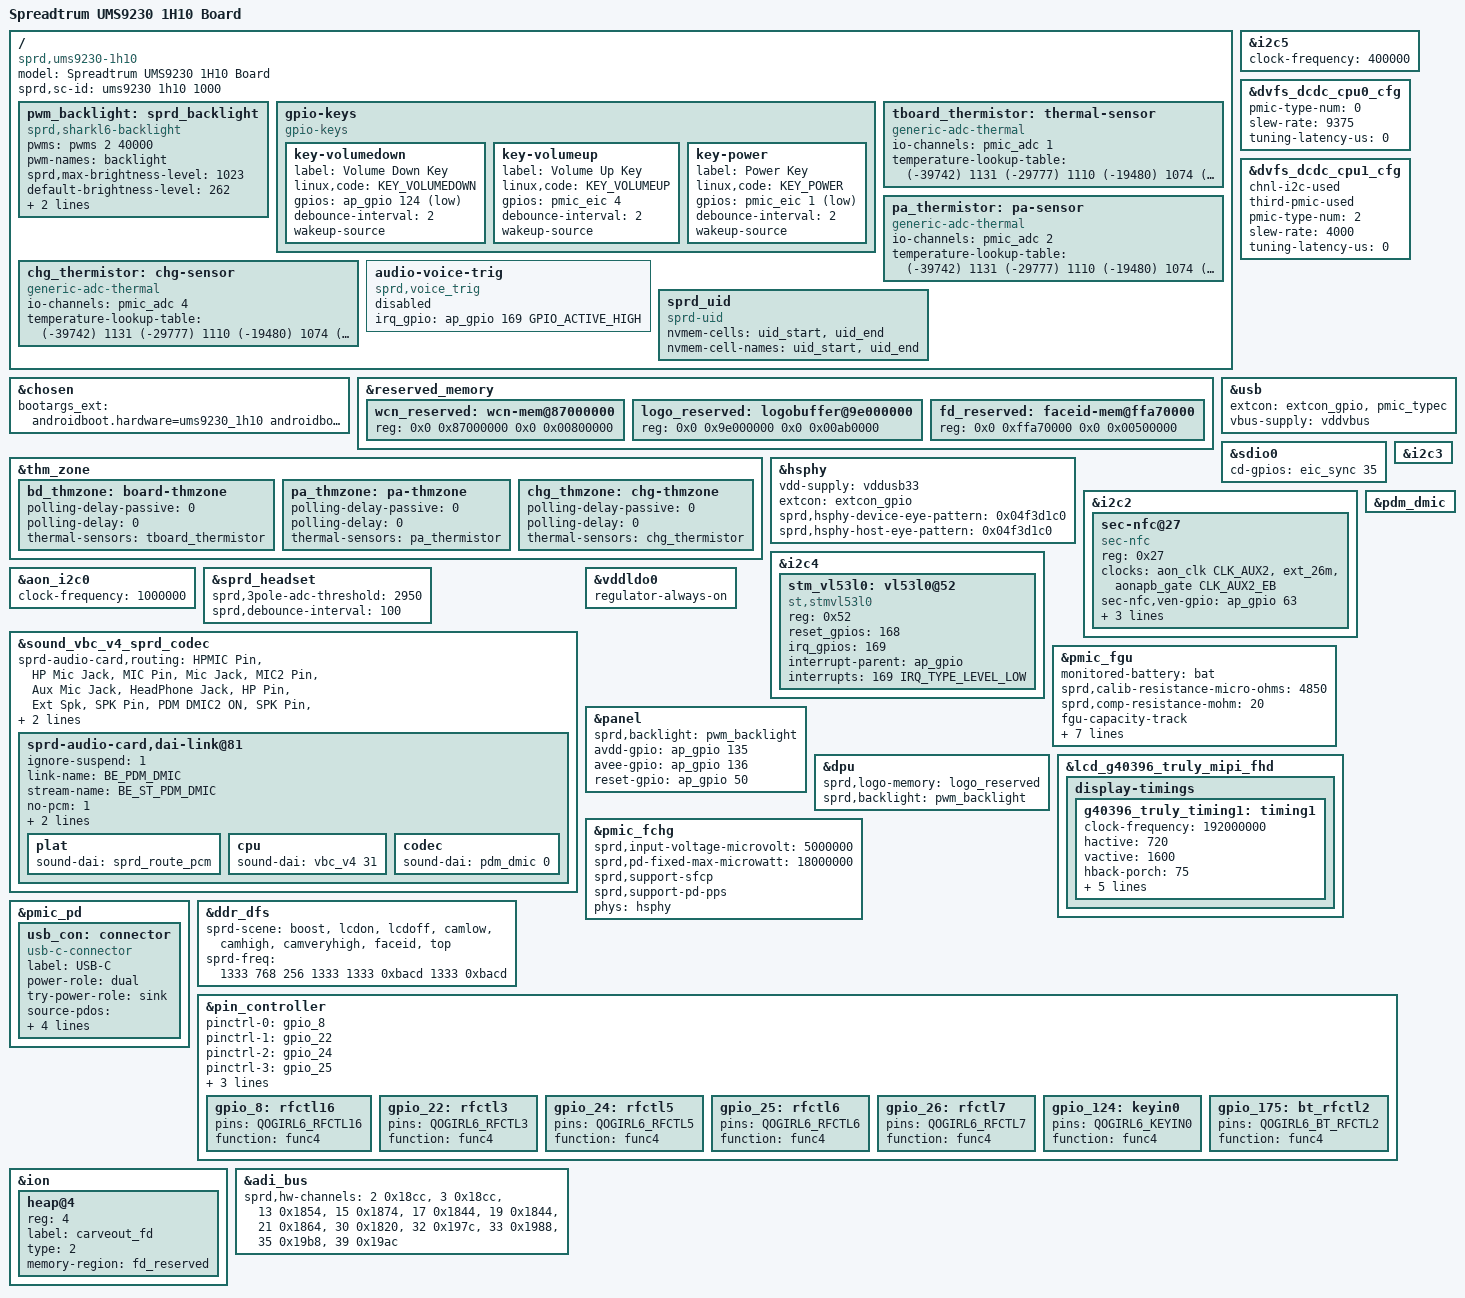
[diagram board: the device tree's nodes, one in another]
/dts-v1/;
/plugin/;
#include <dt-bindings/input/input.h>
#include <dt-bindings/gpio/gpio.h>
#include <dt-bindings/interrupt-controller/arm-gic.h>
#include <dt-bindings/clock/sprd,ums9230-clk.h>
#include <dt-bindings/mfd/sprd,sc2730-regs.h>
#include <dt-bindings/mfd/sprd,sc2730-mask.h>
#include <dt-bindings/usb/pd.h>
#include "../lcd/lcd_g40396_truly_mipi_fhd.dtsi"
#include "../lcd/lcd_dummy_mipi.dtsi"
#include "../ums9230-wcn.dtsi"

/ {

	model = "Spreadtrum UMS9230 1H10 Board";

	compatible = "sprd,ums9230-1h10";

	sprd,sc-id = "ums9230 1h10 1000";
	fragment {
		target-path = "/";
		__overlay__ {
			pwm_backlight: sprd_backlight {
				compatible = "sprd,sharkl6-backlight";
				pwms = <&pwms 2 40000>;
				pwm-names = "backlight";
				sprd,max-brightness-level = <1023>;
				default-brightness-level = <262>;
				sprd,brightness-scale = <1023>;
				brightness-levels = <
					/*		  0   3   4   5   6   7
					  8   9  10  11  12  13  14  16  17  18
					 19  20  21  22  23  24  25  26  27  28
					 29  31  33  35  37  39  41  43  45  47
					 48  50  52  54  56  58  60  62  64  67
					 69  72  74  76  78  80  82  84  86  88
					 90  92  94  96  98 100 102 104 107 109
					112 114 116 118 120 122 124 126 128 130
					132 134 136 138 140 142 144 147 149 151
					154 156 158 160 162 164 166 168 170 172
					175 178 181 184 187 190 193 196 199 203
					205 208 211 214 217 220 223 226 229 234
					237 240 243 247 250 253 256 259 263 266
					269 270 274 277 280 283 287 290 294 297
					300 303 307 310 314 318 325 329 334 339
					340 343 347 350 354 358 365 369 374 380
					382 385 389 392 396 400 407 411 416 422
					426 430 434 438 442 446 452 457 460 464
					470 474 480 486 492 498 504 508 512 516
					522 527 532 536 540 545 550 555 561 568
					574 579 584 589 594 600 605 610 615 620
					625 630 635 641 647 652 657 662 667 673
					688 694 700 706 712 716 720 725 730 735
					740 746 752 758 764 770 776 782 790 798
					803 810 817 825 832 840 845 850 855 861
					866 872 878 884 890 896 903 911 918 924*/
				>;
			};

			gpio-keys {
				compatible = "gpio-keys";

				key-volumedown {
					label = "Volume Down Key";
					linux,code = <KEY_VOLUMEDOWN>;
					gpios = <&ap_gpio 124 GPIO_ACTIVE_LOW>;
					debounce-interval = <2>;
					wakeup-source;
				};

				key-volumeup {
					label = "Volume Up Key";
					linux,code = <KEY_VOLUMEUP>;
					gpios = <&pmic_eic 4 GPIO_ACTIVE_HIGH>;
					debounce-interval = <2>;
					wakeup-source;
				};

				key-power {
					label = "Power Key";
					linux,code = <KEY_POWER>;
					gpios = <&pmic_eic 1 GPIO_ACTIVE_LOW>;
					debounce-interval = <2>;
					wakeup-source;
				};
			};


			tboard_thermistor: thermal-sensor {
				compatible = "generic-adc-thermal";
				#thermal-sensor-cells = <0>;
				io-channels = <&pmic_adc 1>;
				io-channel-names = "sensor-channel";
				temperature-lookup-table = <
					(-39742) 1131
					(-29777) 1110
					(-19480) 1074
					(-4679) 983
					10110 838
					24805 654
					44922 413
					54903 316
					64895 238
					74884 178
					84883 133
					94883 100
					104880 75
					114889 57
					124872 43 >;
			};

			pa_thermistor: pa-sensor {
				compatible = "generic-adc-thermal";
				#thermal-sensor-cells = <0>;
				io-channels = <&pmic_adc 2>;
				io-channel-names = "sensor-channel";
				temperature-lookup-table = <
					(-39742) 1131
					(-29777) 1110
					(-19480) 1074
					(-4679) 983
					10110 838
					24805 654
					44922 413
					54903 316
					64895 238
					74884 178
					84883 133
					94883 100
					104880 75
					114889 57
					124872 43 >;
			};

			chg_thermistor: chg-sensor {
				compatible = "generic-adc-thermal";
				#thermal-sensor-cells = <0>;
				io-channels = <&pmic_adc 4>;
				io-channel-names = "sensor-channel";
				temperature-lookup-table = <
					(-39742) 1131
					(-29777) 1110
					(-19480) 1074
					(-4679) 983
					10110 838
					24805 654
					44922 413
					54903 316
					64895 238
					74884 178
					84883 133
					94883 100
					104880 75
					114889 57
					124872 43 >;
			};

			audio-voice-trig {
				status = "disable";
				compatible = "sprd,voice_trig";
				irq_gpio = <&ap_gpio 169 GPIO_ACTIVE_HIGH>;
			};

			sprd_uid {
				compatible = "sprd-uid";
				nvmem-cells = <&uid_start>, <&uid_end>;
				nvmem-cell-names = "uid_start", "uid_end";
			};

		};
	};
};

&chosen {
	bootargs_ext = "androidboot.hardware=ums9230_1h10 androidboot.dtbo_idx=0";
};

&reserved_memory {
	#address-cells = <2>;
	#size-cells = <2>;
	wcn_reserved: wcn-mem@87000000 {
		reg = <0x0 0x87000000 0x0 0x00800000>;
	};

	logo_reserved: logobuffer@9e000000{
		reg = <0x0 0x9e000000 0x0 0x00ab0000>;
	};

	fd_reserved: faceid-mem@ffa70000 {
		reg = <0x0 0xffa70000 0x0 0x00500000>;
	};
};

&thm_zone {
	bd_thmzone: board-thmzone {
		polling-delay-passive = <0>;
		polling-delay = <0>;
		thermal-sensors = <&tboard_thermistor>;
	};

	pa_thmzone: pa-thmzone {
		polling-delay-passive = <0>;
		polling-delay = <0>;
		thermal-sensors = <&pa_thermistor>;
	};

	chg_thmzone: chg-thmzone {
		polling-delay-passive = <0>;
		polling-delay = <0>;
		thermal-sensors = <&chg_thermistor>;
	};
};


&i2c5 {
	status = "okay";
	clock-frequency = <400000>;
	#address-cells = <1>;
	#size-cells = <0>;

};

&dvfs_dcdc_cpu0_cfg {
	pmic-type-num = <0>;
	slew-rate = <9375>; /* 9375uV/us */
	tuning-latency-us = <0>;
};

&dvfs_dcdc_cpu1_cfg {
	chnl-i2c-used;
	third-pmic-used;
	pmic-type-num = <2>;
	slew-rate = <4000>; /* 4000uV/us */
	tuning-latency-us = <0>;
};

&hsphy {
	vdd-supply = <&vddusb33>;
	extcon = <&extcon_gpio>;
	sprd,hsphy-device-eye-pattern = <0x04f3d1c0>;
	sprd,hsphy-host-eye-pattern = <0x04f3d1c0>;
	status = "okay";
};

&usb {
	extcon = <&extcon_gpio>, <&pmic_typec>;
	vbus-supply = <&vddvbus>;
	status = "okay";
};

&sdio0 {
	cd-gpios = <&eic_sync 35 GPIO_ACTIVE_HIGH>;
};

&i2c2 {
	status = "okay";
	#address-cells = <1>;
	#size-cells = <0>;
	sec-nfc@27 {
		compatible = "sec-nfc";
		reg = <0x27>;
		clock-names = "nfc_clk","source","enable";
		clocks = <&aon_clk CLK_AUX2>, <&ext_26m>, <&aonapb_gate CLK_AUX2_EB>;
		sec-nfc,ven-gpio = <&ap_gpio 63 0>;
		sec-nfc,firm-gpio = <&ap_gpio 61 0>;
		sec-nfc,irq-gpio = <&ap_gpio 62 0>;
		sec-nfc,clk-req = <&ap_gpio 60 0>;
	};

};

&i2c3 {
	status = "okay";
	#address-cells = <1>;
	#size-cells = <0>;
};

&i2c4 {
	status = "okay";
	#address-cells = <1>;
	#size-cells = <0>;

	stm_vl53l0: vl53l0@52 {
		compatible = "st,stmvl53l0";
		reg = <0x52>;
		reset_gpios = <168>;
		irq_gpios = <169>;
		interrupt-parent = <&ap_gpio>;
		interrupts = <169 IRQ_TYPE_LEVEL_LOW>;
	};
};

&aon_i2c0 {
	status = "okay";
	clock-frequency = <1000000>;
};

&sprd_headset {
	status = "okay";
	sprd,3pole-adc-threshold = <2950>;
	sprd,debounce-interval = <100>;
};

&pdm_dmic {
	status = "okay";
};

&sound_vbc_v4_sprd_codec {
	status = "okay";
	sprd-audio-card,routing =
		"HPMIC Pin", "HP Mic Jack",
		"MIC Pin", "Mic Jack",
		"MIC2 Pin", "Aux Mic Jack",
		"HeadPhone Jack", "HP Pin",
		"Ext Spk", "SPK Pin",
		"PDM DMIC2 ON", "SPK Pin",
		"Ext Spk", "PDM_DMIC2",
		"DMIC Pin", "DMic Jack",
		"DMIC1 Pin", "DMic1 Jack",
		"Ext Ear", "EAR Pin";

	/* 63: pdm dmic */
	sprd-audio-card,dai-link@81 {
		ignore-suspend = <1>;
		link-name = "BE_PDM_DMIC";
		stream-name = "BE_ST_PDM_DMIC";
		no-pcm = <1>;
		dpcm-capture = <1>;
		be-id = <0>;
		//dai-format = "i2s";
		plat {
			sound-dai = <&sprd_route_pcm>;
		};
		cpu {
			sound-dai = <&vbc_v4 31>;
		};
		codec {
			sound-dai = <&pdm_dmic 0>;
		};
	};
};

&vddldo0 {
	regulator-always-on;
};

&pmic_fgu {
	monitored-battery = <&bat>;
	sprd,calib-resistance-micro-ohms = <4850>;
	sprd,comp-resistance-mohm = <20>;

	fgu-capacity-track;
	phys = <&hsphy>;

	sprd,relax-counter-threshold = <580>;
	sprd,relax-current-threshold = <30>;
	sprd,capacity-sleep-calibration;

	sprd,capacity-boot-calibration;
	sprd,capacity-charge-cycle;
	sprd,basp;
};

&panel {
	sprd,backlight = <&pwm_backlight>;

	avdd-gpio = <&ap_gpio 135 GPIO_ACTIVE_HIGH>;
	avee-gpio = <&ap_gpio 136 GPIO_ACTIVE_HIGH>;
	reset-gpio = <&ap_gpio 50 GPIO_ACTIVE_HIGH>;
};

&dpu {
	sprd,logo-memory = <&logo_reserved>;

	sprd,backlight = <&pwm_backlight>;
};

&lcd_g40396_truly_mipi_fhd {
	display-timings {
		g40396_truly_timing1: timing1 {
			clock-frequency = <192000000>;
			hactive = <720>;
			vactive = <1600>;
			hback-porch = <75>;
			hfront-porch = <75>;
			vback-porch = <32>;
			vfront-porch = <8>;
			hsync-len = <75>;
			vsync-len = <8>;
		};
	};
};

&pmic_fchg {
	status = "okay";
	sprd,input-voltage-microvolt = <5000000>;
	sprd,pd-fixed-max-microwatt = <18000000>;
	sprd,support-sfcp;
	sprd,support-pd-pps;
	phys = <&hsphy>;
};

&pmic_pd {
	status = "okay";
	usb_con: connector {
		compatible = "usb-c-connector";
		label = "USB-C";
		power-role = "dual";
		try-power-role = "sink";
		source-pdos = <PDO_FIXED(5000, 400, PDO_FIXED_USB_COMM)>;
		sink-pdos = <PDO_FIXED(5000, 3000, PDO_FIXED_USB_COMM)
			     PDO_PPS_APDO(3300, 11000, 3000)>;
		op-sink-microwatt = <10000000>;
	};
};

&ddr_dfs {
	  sprd-scene = "boost", "lcdon", "lcdoff", "camlow",
			"camhigh", "camveryhigh", "faceid", "top";
	  sprd-freq = <1333 768 256 1333 1333 0xbacd 1333 0xbacd>;
};

&pin_controller {
	pinctrl-names =
	/* rfctl16 ,rfctl3, rfctl5 */
	"gpio_8", "gpio_22", "gpio_24",
	/* rfctl6, rfctl7, keyin0 */
	"gpio_25", "gpio_26", "gpio_124",
	/* bt_rfctl2 */
	"gpio_175";
	pinctrl-0 = <&gpio_8>;
	pinctrl-1 = <&gpio_22>;
	pinctrl-2 = <&gpio_24>;
	pinctrl-3 = <&gpio_25>;
	pinctrl-4 = <&gpio_26>;
	pinctrl-5 = <&gpio_124>;
	pinctrl-6 = <&gpio_175>;

	gpio_8: rfctl16 {
		pins = "QOGIRL6_RFCTL16";
		function = "func4";
	};

	gpio_22: rfctl3 {
		pins = "QOGIRL6_RFCTL3";
		function = "func4";
	};

	gpio_24: rfctl5 {
		pins = "QOGIRL6_RFCTL5";
		function = "func4";
	};

	gpio_25: rfctl6 {
		pins = "QOGIRL6_RFCTL6";
		function = "func4";
	};

	gpio_26: rfctl7 {
		pins = "QOGIRL6_RFCTL7";
		function = "func4";
	};

	gpio_124: keyin0 {
		pins = "QOGIRL6_KEYIN0";
		function = "func4";
	};

	gpio_175: bt_rfctl2 {
		pins = "QOGIRL6_BT_RFCTL2";
		function = "func4";
	};
};

&ion {
	#address-cells = <1>;
	#size-cells = <0>;
	heap@4 {
		reg = <4>;
		label = "carveout_fd";
		type = <2>;
		memory-region = <&fd_reserved>;
	};
};

&adi_bus {
	sprd,hw-channels = <2 0x18cc>, <3 0x18cc>, <13 0x1854>, <15 0x1874>,
			<17 0x1844>, <19 0x1844>, <21 0x1864>, <30 0x1820>,
			<32 0x197c>, <33 0x1988>, <35 0x19b8>, <39 0x19ac>;
};
